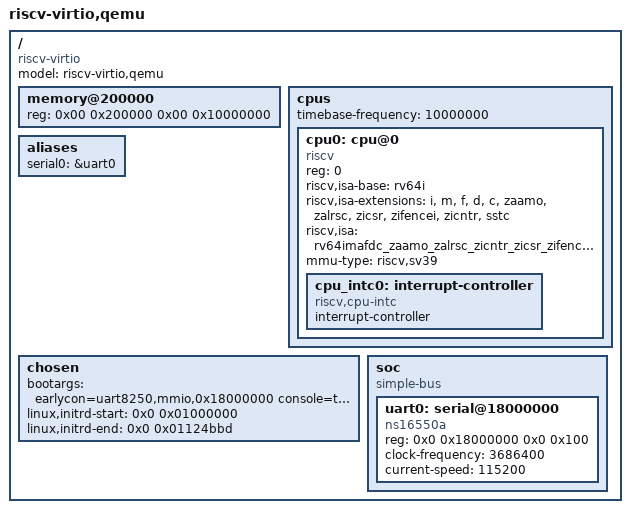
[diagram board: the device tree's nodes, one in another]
/dts-v1/;

/ {
	#address-cells = <0x02>;
	#size-cells = <0x02>;
	compatible = "riscv-virtio";
	model = "riscv-virtio,qemu";

	memory@200000 {
		device_type = "memory";
		reg = <0x00 0x200000 0x00 0x10000000>;
	};

	cpus {
		#address-cells = <1>;
		#size-cells = <0>;
		timebase-frequency = <10000000>;

		cpu0: cpu@0 {
			device_type = "cpu";
			reg = <0>;
			status = "okay";
			compatible = "riscv";

			riscv,isa-base = "rv64i";
			riscv,isa-extensions = "i", "m", "f", "d", "c", "zaamo", "zalrsc", "zicsr", "zifencei", "zicntr", "sstc";
			riscv,isa = "rv64imafdc_zaamo_zalrsc_zicntr_zicsr_zifencei_sstc";
			mmu-type = "riscv,sv39";

			cpu_intc0: interrupt-controller {
				#interrupt-cells = <1>;
				interrupt-controller;
				compatible = "riscv,cpu-intc";
			};
		};
	};

	aliases {
		serial0 = &uart0;
	};

	chosen {
		bootargs = "earlycon=uart8250,mmio,0x18000000 console=ttyS0,115200 rv8.mode=tvm";
		linux,initrd-start = <0x0 0x01000000>;
		linux,initrd-end = <0x0 0x01124bbd>;
	};

	soc {
		#address-cells = <2>;
		#size-cells = <2>;
		compatible = "simple-bus";
		ranges;

		uart0: serial@18000000 {
			compatible = "ns16550a";
			reg = <0x0 0x18000000 0x0 0x100>;
			clock-frequency = <3686400>;
			current-speed = <115200>;
			status = "okay";
		};
	};
};
